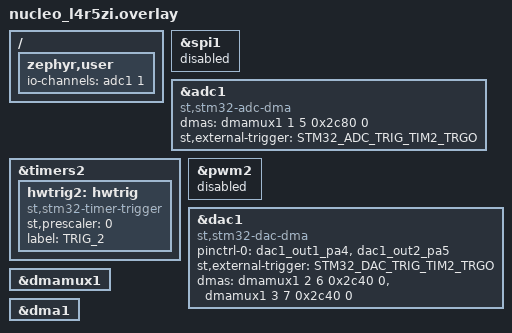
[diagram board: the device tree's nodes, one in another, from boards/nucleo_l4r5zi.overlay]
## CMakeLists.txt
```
# SPDX-License-Identifier: Apache-2.0

cmake_minimum_required(VERSION 3.13.1)

list(APPEND ZEPHYR_EXTRA_MODULES
  ${CMAKE_CURRENT_SOURCE_DIR}/../../stm32-external-drivers
  )

find_package(Zephyr HINTS $ENV{ZEPHYR_BASE})
project(ADC2USB)

target_sources(app PRIVATE src/main.c)
```

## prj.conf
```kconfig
# SPDX-License-Identifier: Apache-2.0

CONFIG_ADC=y
CONFIG_ADC_STM32=n
CONFIG_STM32_EXTERNAL_DRIVERS=y
CONFIG_DMA=y

CONFIG_USB=y
CONFIG_USB_DEVICE_STACK=y
CONFIG_USB_DEVICE_PRODUCT="Zephyr ADC to CDC ACM sample"
CONFIG_USB_CDC_ACM=y
# needed until fixing the send to usb function
CONFIG_USB_CDC_ACM_RINGBUF_SIZE=30000
CONFIG_UART_INTERRUPT_DRIVEN=y

CONFIG_ADC_UART=y
```

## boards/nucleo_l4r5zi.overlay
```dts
/*
 * SPDX-License-Identifier: Apache-2.0
 */

#include <dt-bindings/adc/stm32_adc_dma.h>
#include <dt-bindings/dac/stm32_dac_dma.h>

/ {
	zephyr,user {
		/* adjust channel number according to pinmux in board.dts */
		io-channels = <&adc1 1>;
	};
};

&spi1 {
	status = "disabled";
};

&adc1 {
	compatible = "st,stm32-adc-dma";
	dmas = <&dmamux1 1 5 0x2c80 0>;
	dma-names = "rx";
	st,external-trigger = <STM32_ADC_TRIG_TIM2_TRGO>;
};

&timers2 {
	hwtrig2: hwtrig {
		compatible = "st,stm32-timer-trigger";
		status = "okay";
		st,prescaler = <0>;
		label = "TRIG_2";
	};
};

&pwm2 {
	status = "disabled";
};

&dac1 {
	compatible = "st,stm32-dac-dma";
	status = "okay";
	pinctrl-0 = <&dac1_out1_pa4>, <&dac1_out2_pa5>;
	st,external-trigger = <STM32_DAC_TRIG_TIM2_TRGO>;
	dmas = <&dmamux1 2 6 0x2c40 0>, <&dmamux1 3 7 0x2c40 0>;
	dma-names = "channel1", "channel2";
};

&dmamux1 {
	status = "okay";
};

&dma1 {
	status = "okay";
};
```

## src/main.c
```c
/*
 * Copyright (c) 2020 Libre Solar Technologies GmbH
 *
 * SPDX-License-Identifier: Apache-2.0
 */

#include <zephyr.h>
#include <sys/printk.h>
#include <drivers/adc.h>
#include <drivers/pwm.h>
#include <usb/usb_device.h>
#include <drivers/uart.h>
#include <logging/log.h>
#include <drivers/dac.h>
#include <drivers/hwtrig.h>
#include <drivers/dac_ext.h>

LOG_MODULE_REGISTER(adc_acm, LOG_LEVEL_INF);

static const struct dac_channel_cfg dac_ch_cfg1 = {
	.channel_id  = 1,
	.resolution  = 12
};

static uint16_t values1[4096];

uint16_t curr_values1_pos = 0;

void my_dac_callback(const struct device *dev_dac, uint8_t channel, void *arg)
{
	if (channel == 1) {
		int ret = dac_ext_fill_buffer(dev_dac, channel,
				(uint8_t *)&values1[curr_values1_pos], 4096);
		curr_values1_pos = (curr_values1_pos + 2048) % 4096;
	}
}

void main(void)
{
	int ret;
	const struct device *dev_trig = device_get_binding("TRIG_2");
	const struct device *dev_dac = device_get_binding("DAC_1");

	if (!dev_dac) {
		printk("DAC device not found\n");
		return;
	}

	if (!dev_trig) {
		printk("TRIG device not found\n");
		return;
	}

	ret = dac_channel_setup(dev_dac, &dac_ch_cfg1);

	if (ret != 0) {
		printk("Setting up of DAC channel failed with code %d\n", ret);
		return;
	}

	dac_ext_callback_set(dev_dac, my_dac_callback, NULL);

	ret = dac_ext_start_continuous(dev_dac, 1);

	for (uint16_t i = 0; i < ARRAY_SIZE(values1); ++i) {
		values1[i] = i;
	}

	dac_ext_fill_buffer(dev_dac, 1, (uint8_t *)values1, sizeof(values1));
	curr_values1_pos = 2048;

	k_sleep(K_SECONDS(10));

	// uint32_t freq = 40000; // 40 [KHz]
	uint32_t freq = 1000; // 1 [KHz]
	hwtrig_enable(dev_trig, &freq);
}
```
